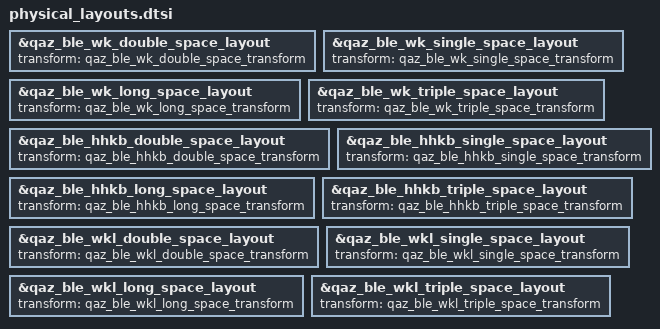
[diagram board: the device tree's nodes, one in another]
#include "layouts/WK_DOUBLE_SPACE.dtsi"
#include "layouts/WK_SINGLE_SPACE.dtsi"
#include "layouts/WK_LONG_SPACE.dtsi"
#include "layouts/WK_TRIPLE_SPACE.dtsi"
#include "layouts/HHKB_DOUBLE_SPACE.dtsi"
#include "layouts/HHKB_SINGLE_SPACE.dtsi"
#include "layouts/HHKB_LONG_SPACE.dtsi"
#include "layouts/HHKB_TRIPLE_SPACE.dtsi"
#include "layouts/WKL_DOUBLE_SPACE.dtsi"
#include "layouts/WKL_SINGLE_SPACE.dtsi"
#include "layouts/WKL_LONG_SPACE.dtsi"
#include "layouts/WKL_TRIPLE_SPACE.dtsi"
#include "layouts/position_map.dtsi"

&qaz_ble_wk_double_space_layout {
    transform = <&qaz_ble_wk_double_space_transform>;
};

&qaz_ble_wk_single_space_layout {
    transform = <&qaz_ble_wk_single_space_transform>;
};
&qaz_ble_wk_long_space_layout {
    transform = <&qaz_ble_wk_long_space_transform>;
};
&qaz_ble_wk_triple_space_layout {
    transform = <&qaz_ble_wk_triple_space_transform>;
};
&qaz_ble_hhkb_double_space_layout {
    transform = <&qaz_ble_hhkb_double_space_transform>;
};

&qaz_ble_hhkb_single_space_layout {
    transform = <&qaz_ble_hhkb_single_space_transform>;
};
&qaz_ble_hhkb_long_space_layout {
    transform = <&qaz_ble_hhkb_long_space_transform>;
};
&qaz_ble_hhkb_triple_space_layout {
    transform = <&qaz_ble_hhkb_triple_space_transform>;
};
&qaz_ble_wkl_double_space_layout {
    transform = <&qaz_ble_wkl_double_space_transform>;
};

&qaz_ble_wkl_single_space_layout {
    transform = <&qaz_ble_wkl_single_space_transform>;
};
&qaz_ble_wkl_long_space_layout {
    transform = <&qaz_ble_wkl_long_space_transform>;
};
&qaz_ble_wkl_triple_space_layout {
    transform = <&qaz_ble_wkl_triple_space_transform>;
};
